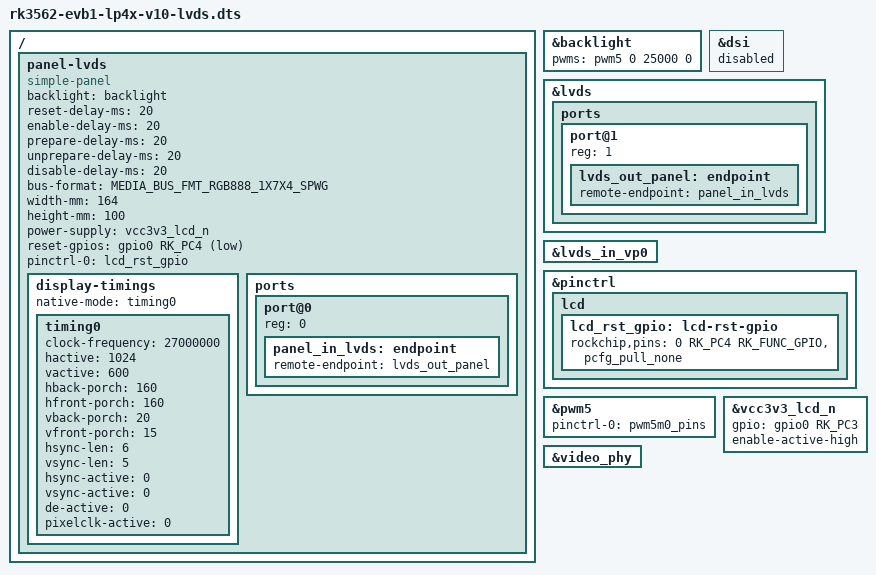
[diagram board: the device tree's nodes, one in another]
// SPDX-License-Identifier: (GPL-2.0+ OR MIT)
/*
 * Copyright (c) 2022 Rockchip Electronics Co., Ltd.
 *
 */

#include <dt-bindings/display/media-bus-format.h>
#include "rk3562-evb1-lp4x-v10.dtsi"
#include "rk3562-android.dtsi"
#include "rk3562-rk817.dtsi"


/ {
	panel-lvds {
		compatible = "simple-panel";
		status = "okay";
		backlight = <&backlight>;
		reset-delay-ms = <20>;
		enable-delay-ms = <20>;
		prepare-delay-ms = <20>;
		unprepare-delay-ms = <20>;
		disable-delay-ms = <20>;
		bus-format = <MEDIA_BUS_FMT_RGB888_1X7X4_SPWG>;
		width-mm = <164>;
		height-mm = <100>;

		power-supply = <&vcc3v3_lcd_n>;
		reset-gpios = <&gpio0 RK_PC4 GPIO_ACTIVE_LOW>;
		pinctrl-names = "default";
		pinctrl-0 = <&lcd_rst_gpio>;

		display-timings {
			native-mode = <&timing0>;

			timing0: timing0 {
				clock-frequency = <27000000>;
				hactive = <1024>;
				vactive = <600>;
				hback-porch = <160>;
				hfront-porch = <160>;
				vback-porch = <20>;
				vfront-porch = <15>;
				hsync-len = <6>;
				vsync-len = <5>;
				hsync-active = <0>;
				vsync-active = <0>;
				de-active = <0>;
				pixelclk-active = <0>;
			};
		};

		ports {
			#address-cells = <1>;
			#size-cells = <0>;

			port@0 {
				reg = <0>;
				panel_in_lvds: endpoint {
					remote-endpoint = <&lvds_out_panel>;
				};
			};
		};
	};

};

&backlight {
	pwms = <&pwm5 0 25000 0>;
	status = "okay";
};

&dsi {
	status = "disabled";
};

&lvds {
	status = "okay";

	ports {
		port@1 {
			reg = <1>;

			lvds_out_panel: endpoint {
				remote-endpoint = <&panel_in_lvds>;
			};
		};
	};
};

&lvds_in_vp0 {
	status = "okay";
};

&pinctrl {
	lcd {
		lcd_rst_gpio: lcd-rst-gpio {
			rockchip,pins = <0 RK_PC4 RK_FUNC_GPIO &pcfg_pull_none>;
		};
	};
};

&pwm5 {
	pinctrl-names = "active";
	pinctrl-0 = <&pwm5m0_pins>;
	status = "okay";
};

&vcc3v3_lcd_n {
	gpio = <&gpio0 RK_PC3 GPIO_ACTIVE_HIGH>;
	enable-active-high;
	status = "okay";
};

&video_phy {
	status = "okay";
};
